# f28004x_erad_counter_regs register map
Vendor: Texas Instruments
Peripheral module from a debugger description file (folder C2000).
Address unit: 16 bits
Registers are 16-bit, read-write, no defined reset value unless marked. A register's access mark holds for its fields unless they carry their own. Offsets are as the file gives them; lines under a group give offsets from that group; [hi:lo] are bit positions; {n}, {i} and the like mark numbered series; 'fields as' and 'values as' point back to an identical list; <NAME> marks a mode.

## ERAD_COUNTER_REGS — ERAD COUNTER Registers
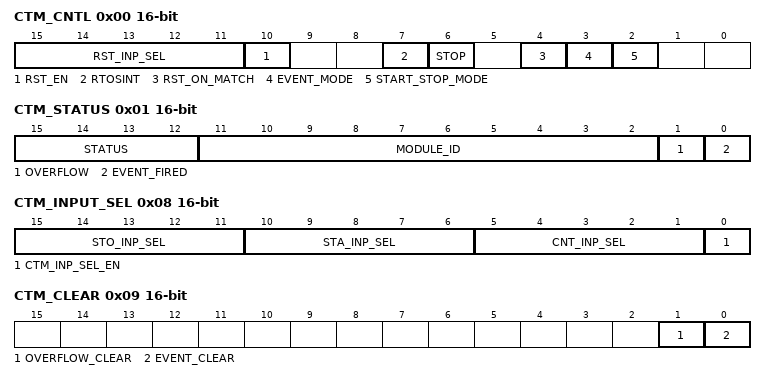
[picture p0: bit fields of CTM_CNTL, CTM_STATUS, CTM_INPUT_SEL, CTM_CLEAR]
0x00 CTM_CNTL — Counter Control Register
  [15:11] RST_INP_SEL — Reset Input select
  [10] RST_EN — Enable Reset
  [7] RTOSINT — RTOSINT bit
  [6] STOP — Stop bit (Halt/No Halt of CPU)
  [4] RST_ON_MATCH — Reset_on_match bit
  [3] EVENT_MODE — Event mode bit
  [2] START_STOP_MODE — Start_stop mode bit
0x01 CTM_STATUS ro — Counter Status Register
  [15:12] STATUS — Status bits
  [11:2] MODULE_ID — Identification bits
  [1] OVERFLOW — Counter Overflowed
  [0] EVENT_FIRED — Counter Event Fired bits
0x02 CTM_REF 32-bit — Counter Reference Register
  [31:0] REF — The counter reference register
0x04 CTM_COUNT 32-bit — Counter Current Value Register
  [31:0] COUNT — The counter value register
0x06 CTM_MAX_COUNT 32-bit — Counter Max Count Value Register
  [31:0] MAX_COUNT — The maximum recorded counter value.
0x08 CTM_INPUT_SEL — Counter Input Select Register
  [15:11] STO_INP_SEL — Stop input select
  [10:6] STA_INP_SEL — Start input select
  [5:1] CNT_INP_SEL — Count input select
  [0] CTM_INP_SEL_EN — Count input select enable
0x09 CTM_CLEAR — Counter Clear Register
  [1] OVERFLOW_CLEAR — Clear OVERFLOW
  [0] EVENT_CLEAR — Clear EVENT_FIRED
